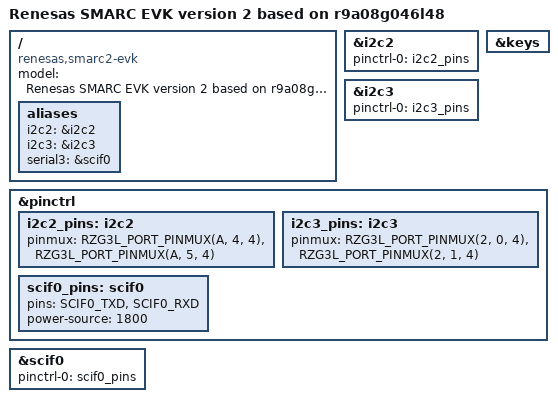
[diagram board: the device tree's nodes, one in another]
// SPDX-License-Identifier: (GPL-2.0-only OR BSD-2-Clause)
/*
 * Device Tree Source for the RZ/G3L SMARC EVK board
 *
 * Copyright (C) 2026 Renesas Electronics Corp.
 */

/dts-v1/;

/* Switch selection settings */
#define RZ_BOOT_MODE3		1
#define SW_DPI_EN		0
#define SW_GPIO4		1
#define SW_I3C_EN		0

#define PMOD_GPIO4		0
#define PMOD_GPIO6		0
#define PMOD_GPIO7		0

#define KEY_1_GPIO		RZG3L_GPIO(J, 3)
#define KEY_2_GPIO		RZG3L_GPIO(6, 4)
#define KEY_3_GPIO		RZG3L_GPIO(6, 5)

#include <dt-bindings/gpio/gpio.h>
#include <dt-bindings/input/input.h>
#include <dt-bindings/pinctrl/renesas,r9a08g046-pinctrl.h>
#include "r9a08g046l48.dtsi"
#include "rzg3l-smarc-som.dtsi"
#include "renesas-smarc2.dtsi"

/ {
	model = "Renesas SMARC EVK version 2 based on r9a08g046l48";
	compatible = "renesas,smarc2-evk", "renesas,rzg3l-smarcm",
		     "renesas,r9a08g046l48", "renesas,r9a08g046";

	aliases {
		i2c2 = &i2c2;
		i2c3 = &i2c3;
		serial3 = &scif0;
	};
};

&i2c2 {
	pinctrl-0 = <&i2c2_pins>;
	pinctrl-names = "default";

	status = "okay";
};

#if !SW_I3C_EN
&i2c3 {
	pinctrl-0 = <&i2c3_pins>;
	pinctrl-names = "default";

	status = "okay";
};
#endif

&keys {
#if !RZ_BOOT_MODE3 || !SW_GPIO4 || PMOD_GPIO4
	/delete-node/ key-1;
#endif

#if SW_DPI_EN || PMOD_GPIO6
	/delete-node/ key-2;
#endif

#if SW_DPI_EN || PMOD_GPIO7
	/delete-node/ key-3;
#endif
};

&pinctrl {
	i2c2_pins: i2c2 {
		pinmux = <RZG3L_PORT_PINMUX(A, 4, 4)>, /* RIIC2_SCL */
			 <RZG3L_PORT_PINMUX(A, 5, 4)>; /* RIIC2_SDA */
	};

	i2c3_pins: i2c3 {
		pinmux = <RZG3L_PORT_PINMUX(2, 0, 4)>, /* RIIC3_SCL */
			 <RZG3L_PORT_PINMUX(2, 1, 4)>; /* RIIC3_SDA */
	};

	scif0_pins: scif0 {
		pins = "SCIF0_TXD", "SCIF0_RXD";
		power-source = <1800>;
	};
};

&scif0 {
	pinctrl-0 = <&scif0_pins>;
	pinctrl-names = "default";
};
